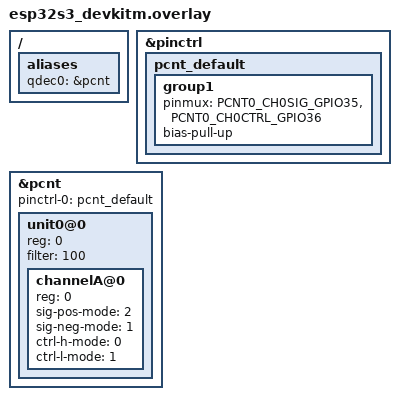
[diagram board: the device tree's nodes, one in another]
/*
 * SPDX-License-Identifier: Apache-2.0
 *
 * Copyright (c) 2023 Espressif Systems (Shanghai) Co., Ltd.
 */

#include <dt-bindings/pinctrl/esp32s3-pinctrl.h>

/ {
	aliases {
		qdec0 = &pcnt;
	};
};

&pinctrl {
	pcnt_default: pcnt_default {
		group1 {
			pinmux = <PCNT0_CH0SIG_GPIO35>,
				<PCNT0_CH0CTRL_GPIO36>;
			bias-pull-up;
		};
	};
};

&pcnt {
	pinctrl-0 = <&pcnt_default>;
	pinctrl-names = "default";
	status = "okay";
	#address-cells = <1>;
	#size-cells = <0>;
	unit0@0 {
		reg = <0>;
		#address-cells = <1>;
		#size-cells = <0>;
		filter = <100>;
		channelA@0 {
			reg = <0>;
			sig-pos-mode = <2>;
			sig-neg-mode = <1>;
			ctrl-h-mode = <0>;
			ctrl-l-mode = <1>;
		};
	};
};
